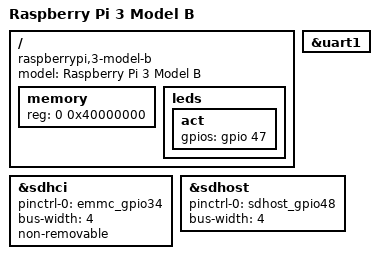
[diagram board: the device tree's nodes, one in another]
/dts-v1/;
#include "bcm2837.dtsi"
#include "bcm2835-rpi.dtsi"
#include "bcm283x-rpi-smsc9514.dtsi"
#include "bcm283x-rpi-usb-host.dtsi"

/ {
	compatible = "raspberrypi,3-model-b", "brcm,bcm2837";
	model = "Raspberry Pi 3 Model B";

	memory {
		reg = <0 0x40000000>;
	};

	leds {
		act {
			gpios = <&gpio 47 0>;
		};
	};
};

&uart1 {
	status = "okay";
};

/* SDHCI is used to control the SDIO for wireless */
&sdhci {
	pinctrl-names = "default";
	pinctrl-0 = <&emmc_gpio34>;
	status = "okay";
	bus-width = <4>;
	non-removable;
};

/* SDHOST is used to drive the SD card */
&sdhost {
	pinctrl-names = "default";
	pinctrl-0 = <&sdhost_gpio48>;
	status = "okay";
	bus-width = <4>;
};
